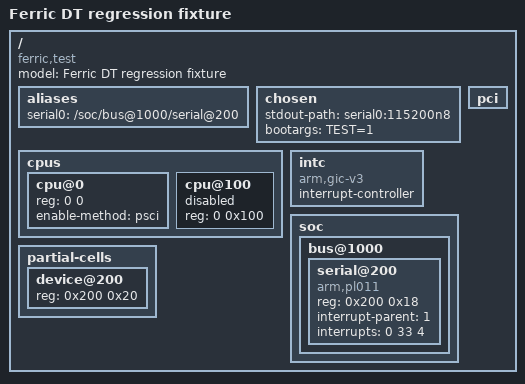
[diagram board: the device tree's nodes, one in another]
/dts-v1/;
/memreserve/ 0x1000 0x100;
/ {
    #address-cells = <2>;
    #size-cells = <2>;
    model = "Ferric DT regression fixture";
    compatible = "ferric,test";
    aliases { serial0 = "/soc/bus@1000/serial@200"; };
    chosen { stdout-path = "serial0:115200n8"; bootargs = "TEST=1"; };
    cpus {
        #address-cells = <2>;
        #size-cells = <0>;
        cpu@0 { device_type = "cpu"; reg = <0 0>; enable-method = "psci"; };
        cpu@100 { device_type = "cpu"; reg = <0 0x100>; status = "disabled"; };
    };
    intc {
        compatible = "arm,gic-v3";
        phandle = <1>;
        interrupt-controller;
        #address-cells = <0>;
        #interrupt-cells = <3>;
    };
    soc {
        #address-cells = <2>;
        #size-cells = <2>;
        ranges;
        bus@1000 {
            #address-cells = <1>;
            #size-cells = <1>;
            ranges = <0 0 0x1000 0x1000>;
            serial@200 {
                compatible = "arm,pl011", "arm,primecell";
                reg = <0x200 0x18>;
                interrupt-parent = <1>;
                interrupts = <0 33 4>;
                clock-names = "apb_pclk", "uartclk";
            };
        };
    };
    partial-cells {
        #address-cells = <1>;
        device@200 { reg = <0x200 0x20>; };
    };
    pci {
        #address-cells = <3>;
        #size-cells = <2>;
        ranges = <0x02000000 0 0 0 0x40000000 0 0x1000>;
    };
};
